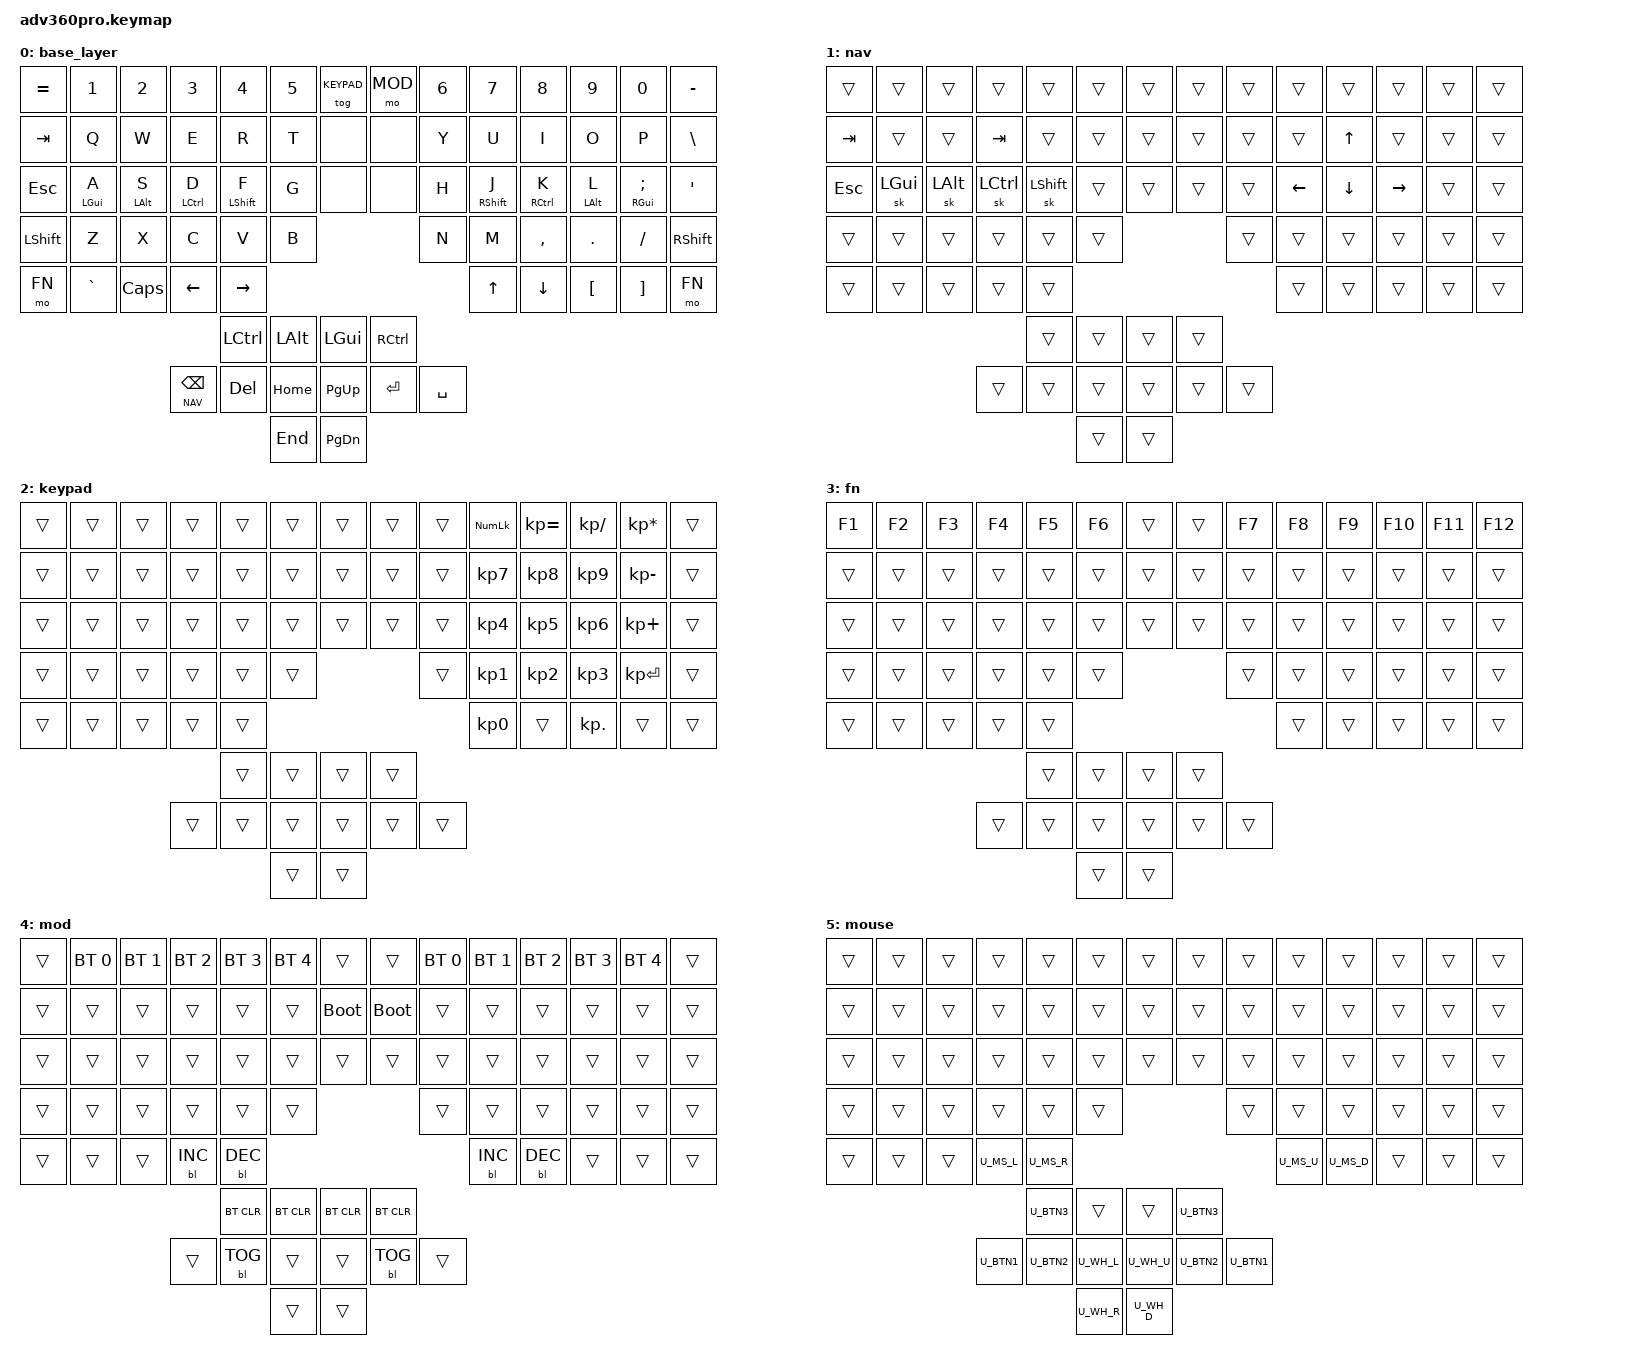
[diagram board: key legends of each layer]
#include <behaviors.dtsi>
#include <dt-bindings/zmk/keys.h>
#include <dt-bindings/zmk/bt.h>
#include <dt-bindings/zmk/outputs.h>
#include <dt-bindings/zmk/rgb.h>
#include <dt-bindings/zmk/backlight.h>

/* definitions for mouse layer */
#include "mouse.dtsi"

#define ___ &trans

#define QWERTY 0
#define NAV 1
#define KEYPAD 2
#define FN 3
#define MOD 4
#define MS 5

/ {
    /* remove unused keys from layout and move thumb cluster to bottom */
    chosen {
        zmk,matrix_transform = &urobs_transform;
    };
    
    behaviors {
        bhm: balanced_homerow_mods {
            compatible = "zmk,behavior-hold-tap";
            label = "HOMEROW_MODS";
            #binding-cells = <2>;
            tapping-term-ms = <200>;    // <---[[moderate duration]]
            quick-tap-ms = <0>;
            flavor = "balanced";
            bindings = <&kp>, <&kp>;
        };
    };

    keymap {
        compatible = "zmk,keymap";

        base_layer {
            bindings = <
                &kp EQUAL &kp N1      &kp N2      &kp N3        &kp N4        &kp N5    &tog KEYPAD    &mo MOD   &kp N6    &kp N7       &kp N8       &kp N9      &kp N0         &kp MINUS
                &kp TAB   &kp Q       &kp W       &kp E         &kp R         &kp T     &none          &none     &kp Y     &kp U        &kp I        &kp O       &kp P          &kp BSLH
                &kp ESC   &bhm LGUI A &bhm LALT S &bhm LCTRL D  &bhm LSHIFT F &kp G     &none          &none     &kp H     &bhm RSHFT J &bhm RCTRL K &bhm LALT L &bhm RGUI SEMI &kp SQT
                &kp LSHFT &kp Z       &kp X       &kp C         &kp V         &kp B                              &kp N     &kp M        &kp COMMA    &kp DOT     &kp FSLH       &kp RSHFT
                &mo FN    &kp GRAVE   &kp CAPS    &kp LEFT      &kp RIGHT                                                  &kp UP       &kp DOWN     &kp LBKT    &kp RBKT       &mo FN
                                                                  &kp LCTRL &kp LALT       &kp LGUI  &kp RCTRL
                                                        &lt NAV BSPC  &kp DEL   &kp HOME       &kp PG_UP &kp ENTER &kp SPACE
                                                                            &kp END        &kp PG_DN
            >;
        };

        nav {
            bindings = <
                ___       ___       ___         ___         ___         ___     ___            ___       ___     ___       ___       ___        ___  ___
                &kp TAB   ___       ___         &kp TAB     ___         ___     ___            ___       ___     ___       &kp UP    ___        ___  ___
                &kp ESC   &sk LGUI  &sk LALT    &sk LCTRL   &sk LSHIFT  ___     ___            ___       ___     &kp LEFT  &kp DOWN  &kp RIGHT  ___  ___
                ___       ___       ___         ___         ___         ___                              ___     ___       ___       ___        ___  ___
                ___       ___       ___         ___         ___                                                  ___       ___       ___        ___  ___
                                                                  ___       ___            ___       ___
                                                        ___       ___       ___            ___       ___       ___
                                                                            ___            ___
            >;
        };

        keypad {
            bindings = <
                ___       ___       ___       ___       ___       ___       ___            ___       ___       &kp KP_NUM &kp KP_EQUAL &kp KP_DIVIDE &kp KP_MULTIPLY ___
                ___       ___       ___       ___       ___       ___       ___            ___       ___       &kp KP_N7  &kp KP_N8    &kp KP_N9     &kp KP_MINUS    ___
                ___       ___       ___       ___       ___       ___       ___            ___       ___       &kp KP_N4  &kp KP_N5    &kp KP_N6     &kp KP_PLUS     ___
                ___       ___       ___       ___       ___       ___                                ___       &kp KP_N1  &kp KP_N2    &kp KP_N3     &kp KP_ENTER    ___
                ___       ___       ___       ___       ___                                                    &kp KP_N0  ___          &kp KP_DOT    ___             ___
                                                                  ___       ___            ___       ___
                                                        ___       ___       ___            ___       ___       ___
                                                                            ___            ___
            >;
        };

        fn {
            bindings = <
                &kp F1    &kp F2    &kp F3    &kp F4    &kp F5    &kp F6    ___            ___       &kp F7    &kp F8    &kp F9    &kp F10   &kp F11   &kp F12
                ___       ___       ___       ___       ___       ___       ___            ___       ___       ___       ___       ___       ___       ___
                ___       ___       ___       ___       ___       ___       ___            ___       ___       ___       ___       ___       ___       ___
                ___       ___       ___       ___       ___       ___                                ___       ___       ___       ___       ___       ___
                ___       ___       ___       ___       ___                                                    ___       ___       ___       ___       ___
                                                                  ___       ___            ___       ___
                                                        ___       ___       ___            ___       ___       ___
                                                                            ___            ___
            >;
        };

        mod {
            bindings = <
                ___       &bt BT_SEL 0 &bt BT_SEL 1 &bt BT_SEL 2 &bt BT_SEL 3 &bt BT_SEL 4 ___              ___         &bt BT_SEL 0 &bt BT_SEL 1     &bt BT_SEL 2 &bt BT_SEL 3 &bt BT_SEL 4 ___
                ___       ___          ___          ___          ___          ___          &bootloader      &bootloader ___          ___              ___          ___          ___          ___
                ___       ___          ___          ___          ___          ___          ___              ___         ___          ___              ___          ___          ___          ___
                ___       ___          ___          ___          ___          ___                                       ___          ___              ___          ___          ___          ___
                ___       ___          ___          &bl BL_INC   &bl BL_DEC                                                          &bl BL_INC       &bl BL_DEC   ___          ___          ___
                                                                              &bt BT_CLR   &bt BT_CLR       &bt BT_CLR  &bt BT_CLR
                                                                 ___          &bl BL_TOG   ___              ___         &bl BL_TOG   ___
                                                                                           ___              ___
            >;
        };

        mouse {
            bindings = <
                ___       ___       ___       ___       ___       ___       ___            ___       ___       ___       ___       ___       ___       ___
                ___       ___       ___       ___       ___       ___       ___            ___       ___       ___       ___       ___       ___       ___
                ___       ___       ___       ___       ___       ___       ___            ___       ___       ___       ___       ___       ___       ___
                ___       ___       ___       ___       ___       ___                                ___       ___       ___       ___       ___       ___
                ___       ___       ___       U_MS_L    U_MS_R                                                 U_MS_U    U_MS_D    ___       ___       ___
                                                                  U_BTN3    ___            ___       U_BTN3
                                                        U_BTN1    U_BTN2    U_WH_L         U_WH_U    U_BTN2    U_BTN1
                                                                            U_WH_R         U_WH_D
            >;
        };

    };

};

